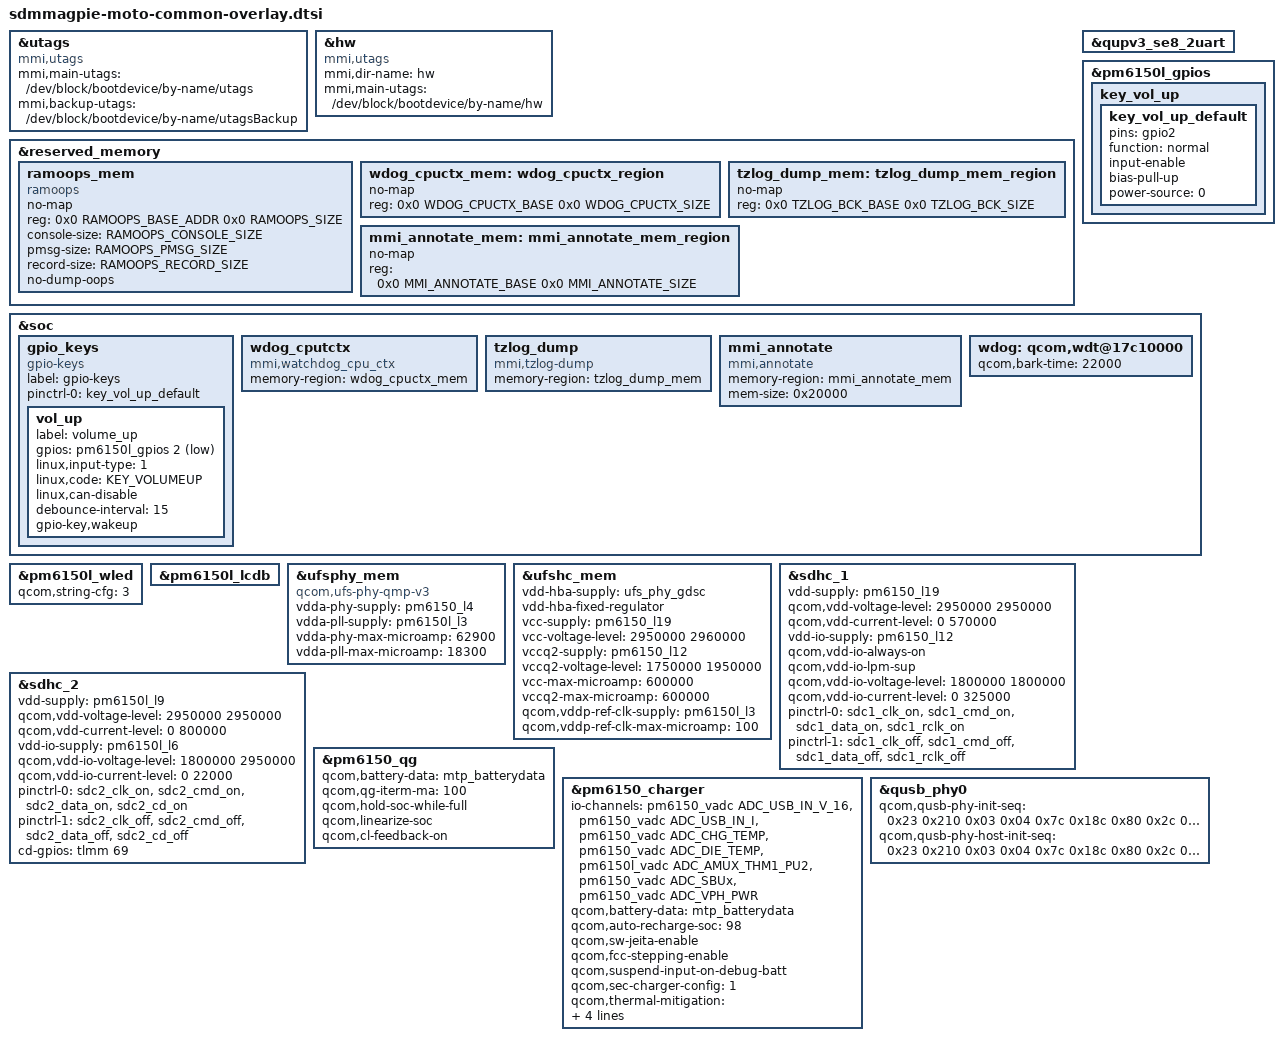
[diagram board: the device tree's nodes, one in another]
/* Copyright (c) 2018, The Linux Foundation. All rights reserved.
 *
 * This program is free software; you can redistribute it and/or modify
 * it under the terms of the GNU General Public License version 2 and
 * only version 2 as published by the Free Software Foundation.
 *
 * This program is distributed in the hope that it will be useful,
 * but WITHOUT ANY WARRANTY; without even the implied warranty of
 * MERCHANTABILITY or FITNESS FOR A PARTICULAR PURPOSE.  See the
 * GNU General Public License for more details.
 */

#include "carrier-channel-ids.dtsi"
#include "sdmmagpie-thermal-overlay.dtsi"
#include <dt-bindings/gpio/gpio.h>
#include <dt-bindings/iio/qcom,spmi-vadc.h>
#include <dt-bindings/input/input.h>
#include "sdmmagpie-sde-display.dtsi"
#include "dsi-panel-mot-dummy-qhd-video.dtsi"
#include <dt-bindings/moto/moto-mem-reserve.h>

&utags {
	compatible = "mmi,utags";
	mmi,main-utags = "/dev/block/bootdevice/by-name/utags";
	mmi,backup-utags = "/dev/block/bootdevice/by-name/utagsBackup";
};

&hw {
	compatible = "mmi,utags";
	mmi,dir-name = "hw";
	mmi,main-utags = "/dev/block/bootdevice/by-name/hw";
};

&reserved_memory {
	ramoops_mem {
		compatible = "ramoops";
		no-map;
		reg = <0x0 RAMOOPS_BASE_ADDR 0x0 RAMOOPS_SIZE>;
		console-size = <RAMOOPS_CONSOLE_SIZE>;
		pmsg-size = <RAMOOPS_PMSG_SIZE>;
		record-size = <RAMOOPS_RECORD_SIZE>;
		no-dump-oops;
	};

	wdog_cpuctx_mem: wdog_cpuctx_region {
		no-map;
		reg = <0x0 WDOG_CPUCTX_BASE
				0x0 WDOG_CPUCTX_SIZE>;
	};

	tzlog_dump_mem: tzlog_dump_mem_region {
		no-map;
		reg = <0x0  TZLOG_BCK_BASE
				0x0 TZLOG_BCK_SIZE>;
	};

	mmi_annotate_mem: mmi_annotate_mem_region {
		no-map;
		reg = <0x0  MMI_ANNOTATE_BASE
				0x0 MMI_ANNOTATE_SIZE>;
	};
};

&qupv3_se8_2uart {
	status = "ok";
};

&pm6150l_gpios {
	key_vol_up {
		key_vol_up_default: key_vol_up_default {
			pins = "gpio2";
			function = "normal";
			input-enable;
			bias-pull-up;
			power-source = <0>;
		};
	};
};


&soc {
	gpio_keys {
		compatible = "gpio-keys";
		label = "gpio-keys";

		pinctrl-names = "default";
		pinctrl-0 = <&key_vol_up_default>;

		vol_up {
			label = "volume_up";
			gpios = <&pm6150l_gpios 2 GPIO_ACTIVE_LOW>;
			linux,input-type = <1>;
			linux,code = <KEY_VOLUMEUP>;
			linux,can-disable;
			debounce-interval = <15>;
			gpio-key,wakeup;
		};
	};

	wdog_cputctx {
		compatible = "mmi,watchdog_cpu_ctx";
		memory-region = <&wdog_cpuctx_mem>;
	};

	tzlog_dump {
		compatible = "mmi,tzlog-dump";
		memory-region = <&tzlog_dump_mem>;
	};

	mmi_annotate {
		compatible = "mmi,annotate";
		memory-region = <&mmi_annotate_mem>;
		mem-size = <0x20000>;
	};

	wdog: qcom,wdt@17c10000 {
		qcom,bark-time = <22000>;
	};
};



&pm6150l_wled {
	qcom,string-cfg= <3>;
	status = "ok";
};

&pm6150l_lcdb {
	status = "ok";
};

&ufsphy_mem {
	compatible = "qcom,ufs-phy-qmp-v3";

	vdda-phy-supply = <&pm6150_l4>; /* 0.88v */
	vdda-pll-supply = <&pm6150l_l3>; /* 1.2v */
	vdda-phy-max-microamp = <62900>;
	vdda-pll-max-microamp = <18300>;

	status = "ok";
};

&ufshc_mem {
	vdd-hba-supply = <&ufs_phy_gdsc>;
	vdd-hba-fixed-regulator;
	vcc-supply = <&pm6150_l19>;
	vcc-voltage-level = <2950000 2960000>;
	vccq2-supply = <&pm6150_l12>;
	vccq2-voltage-level = <1750000 1950000>;
	vcc-max-microamp = <600000>;
	vccq2-max-microamp = <600000>;

	qcom,vddp-ref-clk-supply = <&pm6150l_l3>;
	qcom,vddp-ref-clk-max-microamp = <100>;

	status = "ok";
};



&sdhc_1 {
	vdd-supply = <&pm6150_l19>;
	qcom,vdd-voltage-level = <2950000 2950000>;
	qcom,vdd-current-level = <0 570000>;

	vdd-io-supply = <&pm6150_l12>;
	qcom,vdd-io-always-on;
	qcom,vdd-io-lpm-sup;
	qcom,vdd-io-voltage-level = <1800000 1800000>;
	qcom,vdd-io-current-level = <0 325000>;

	pinctrl-names = "active", "sleep";
	pinctrl-0 = <&sdc1_clk_on &sdc1_cmd_on &sdc1_data_on &sdc1_rclk_on>;
	pinctrl-1 = <&sdc1_clk_off &sdc1_cmd_off &sdc1_data_off &sdc1_rclk_off>;

	status = "ok";
};

&sdhc_2 {
	vdd-supply = <&pm6150l_l9>;
	qcom,vdd-voltage-level = <2950000 2950000>;
	qcom,vdd-current-level = <0 800000>;

	vdd-io-supply = <&pm6150l_l6>;
	qcom,vdd-io-voltage-level = <1800000 2950000>;
	qcom,vdd-io-current-level = <0 22000>;

	pinctrl-names = "active", "sleep";
	pinctrl-0 = <&sdc2_clk_on  &sdc2_cmd_on &sdc2_data_on &sdc2_cd_on>;
	pinctrl-1 = <&sdc2_clk_off &sdc2_cmd_off &sdc2_data_off &sdc2_cd_off>;

	cd-gpios = <&tlmm 69 GPIO_ACTIVE_HIGH>;

	status = "ok";
};


&pm6150_qg {
	qcom,battery-data = <&mtp_batterydata>;
	qcom,qg-iterm-ma = <100>;
	qcom,hold-soc-while-full;
	qcom,linearize-soc;
	qcom,cl-feedback-on;
};

&pm6150_charger {
	io-channels = <&pm6150_vadc ADC_USB_IN_V_16>,
		<&pm6150_vadc ADC_USB_IN_I>,
		<&pm6150_vadc ADC_CHG_TEMP>,
		<&pm6150_vadc ADC_DIE_TEMP>,
		<&pm6150l_vadc ADC_AMUX_THM1_PU2>,
		<&pm6150_vadc ADC_SBUx>,
		<&pm6150_vadc ADC_VPH_PWR>;
	io-channel-names = "usb_in_voltage",
		"usb_in_current",
		"chg_temp",
		"die_temp",
		"conn_temp",
		"sbux_res",
		"vph_voltage";
	qcom,battery-data = <&mtp_batterydata>;
	qcom,auto-recharge-soc = <98>;
	qcom,sw-jeita-enable;
	qcom,fcc-stepping-enable;
	qcom,suspend-input-on-debug-batt;
	qcom,sec-charger-config = <1>;
	qcom,thermal-mitigation = <4200000 3500000 3000000
			2500000 2000000 1500000 1000000 500000>;
	dpdm-supply = <&qusb_phy0>;
	qcom,charger-temp-max = <800>;
	qcom,smb-temp-max = <800>;
};

&qusb_phy0 {
	qcom,qusb-phy-init-seq =
	/* <value reg_offset> */
		<0x23 0x210 /* PWR_CTRL1 */
		0x03 0x04  /* PLL_ANALOG_CONTROLS_TWO */
		0x7c 0x18c /* PLL_CLOCK_INVERTERS */
		0x80 0x2c  /* PLL_CMODE */
		0x0a 0x184 /* PLL_LOCK_DELAY */
		0x19 0xb4  /* PLL_DIGITAL_TIMERS_TWO */
		0x40 0x194 /* PLL_BIAS_CONTROL_1 */
		0x20 0x198 /* PLL_BIAS_CONTROL_2 */
		0x21 0x214 /* PWR_CTRL2 */
		0x00 0x220 /* IMP_CTRL1 */
		0x18 0x224 /* IMP_CTRL2 */
		0x37 0x240 /* TUNE1 */
		0x29 0x244 /* TUNE2 */
		0xca 0x248 /* TUNE3 */
		0x04 0x24c /* TUNE4 */
		0x03 0x250 /* TUNE5 */
		0x00 0x23c /* CHG_CTRL2 */
		0x22 0x210>; /* PWR_CTRL1 */

	qcom,qusb-phy-host-init-seq =
	/* <value reg_offset> */
		<0x23 0x210 /* PWR_CTRL1 */
		0x03 0x04  /* PLL_ANALOG_CONTROLS_TWO */
		0x7c 0x18c /* PLL_CLOCK_INVERTERS */
		0x80 0x2c  /* PLL_CMODE */
		0x0a 0x184 /* PLL_LOCK_DELAY */
		0x19 0xb4  /* PLL_DIGITAL_TIMERS_TWO */
		0x40 0x194 /* PLL_BIAS_CONTROL_1 */
		0x20 0x198 /* PLL_BIAS_CONTROL_2 */
		0x21 0x214 /* PWR_CTRL2 */
		0x00 0x220 /* IMP_CTRL1 */
		0x18 0x224 /* IMP_CTRL2 */
		0x37 0x240 /* TUNE1 */
		0x29 0x244 /* TUNE2 */
		0xca 0x248 /* TUNE3 */
		0x04 0x24c /* TUNE4 */
		0x03 0x250 /* TUNE5 */
		0x00 0x23c /* CHG_CTRL2 */
		0x22 0x210>; /* PWR_CTRL1 */
};

